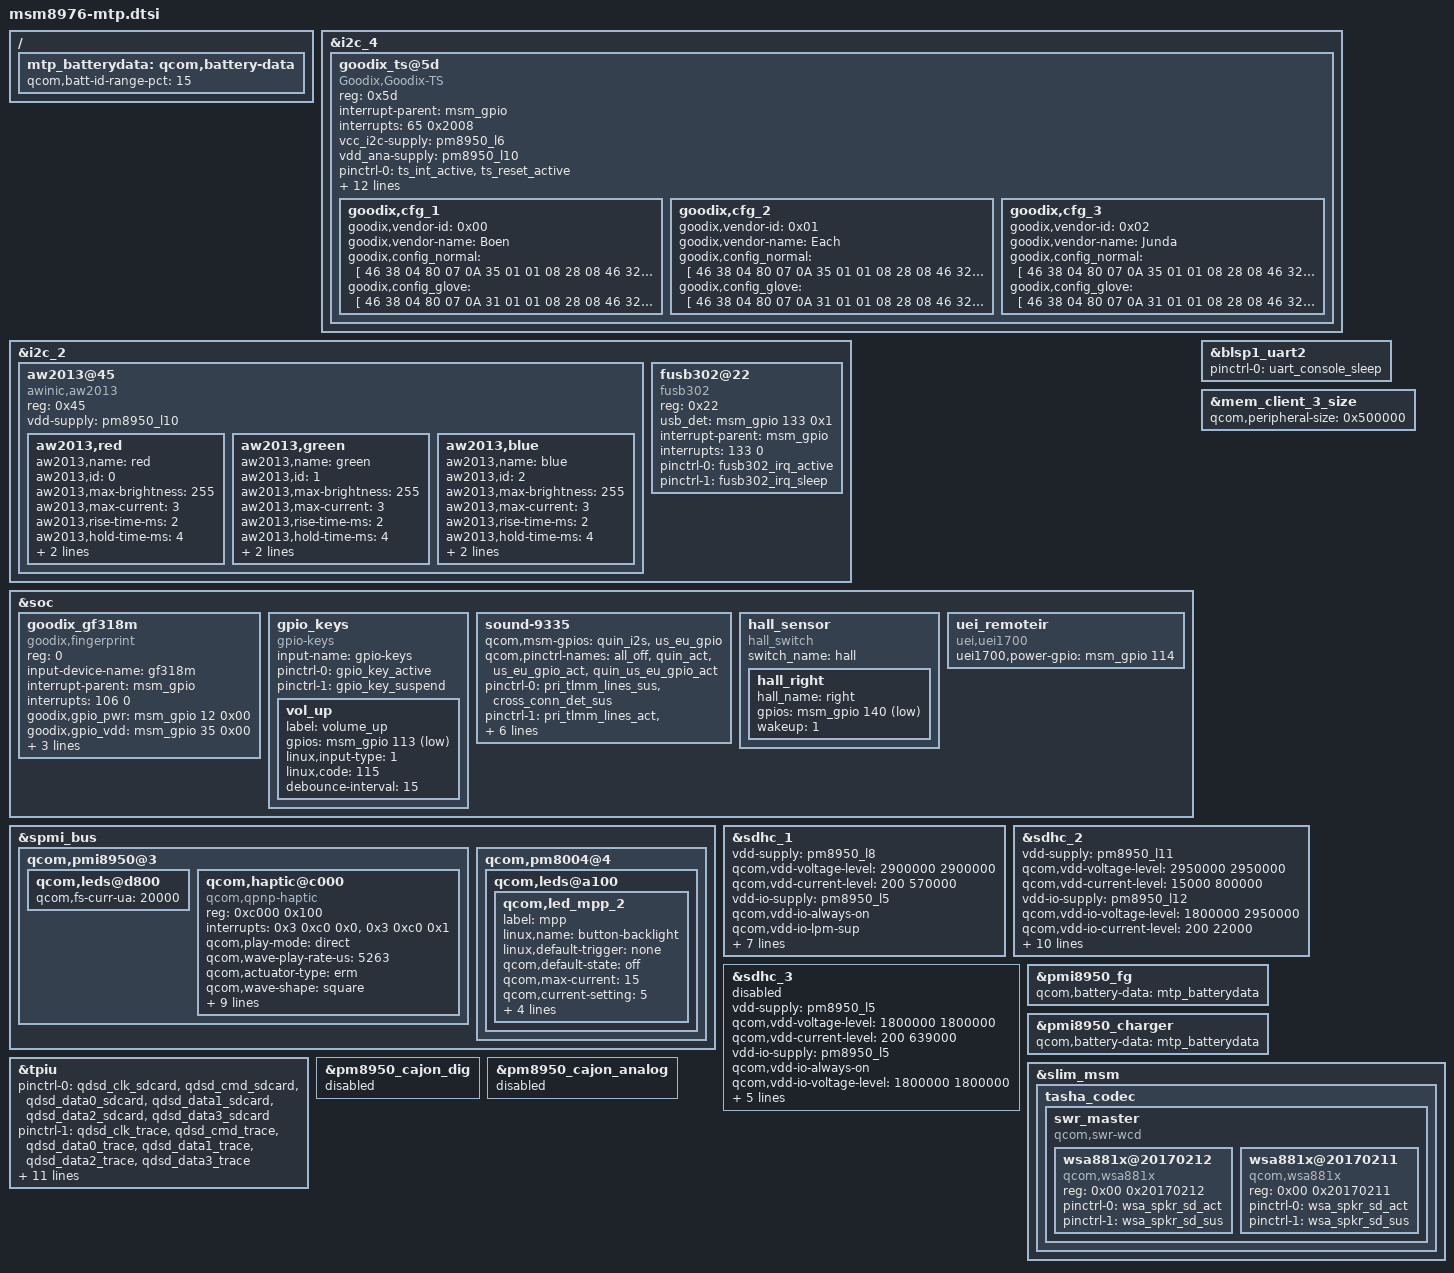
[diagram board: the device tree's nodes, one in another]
/*
 * Copyright (c) 2015, The Linux Foundation. All rights reserved.
 *
 * This program is free software; you can redistribute it and/or modify
 * it under the terms of the GNU General Public License version 2 and
 * only version 2 as published by the Free Software Foundation.
 *
 * This program is distributed in the hope that it will be useful,
 * but WITHOUT ANY WARRANTY; without even the implied warranty of
 * MERCHANTABILITY or FITNESS FOR A PARTICULAR PURPOSE.  See the
 * GNU General Public License for more details.
 */

#include "msm8976-pinctrl.dtsi"
#include "msm8976-camera-sensor-mtp.dtsi"
#include "msm8976-mdss-mtp.dtsi"
#include "msm8976-wsa881x.dtsi"

&i2c_4 { /* BLSP1 QUP4 */
	goodix_ts@5d {
		compatible = "Goodix,Goodix-TS";
		reg = <0x5d>;
		interrupt-parent = <&msm_gpio>;
		interrupts = <65 0x2008>;
		vcc_i2c-supply = <&pm8950_l6>;
		vdd_ana-supply = <&pm8950_l10>;
		/* pins used by touchscreen */
		pinctrl-names = "pmx_ts_active","pmx_ts_suspend";
		pinctrl-0 = <&ts_int_active &ts_reset_active>;
		pinctrl-1 = <&ts_int_suspend &ts_reset_suspend>;
		goodix,irq-gpio = <&msm_gpio 65 0x2008>;
		goodix,reset-gpio = <&msm_gpio 64 0x0>;
		goodix,irq_flags = <0x2>;
		goodix,pixel = <1080 1920>;
		goodix,pwr_ctrl = <1>;
		goodix,vddio = "vcc_i2c";
		goodix,vdd = "vdd_ana";
		goodix,ic_type = "GT915L";
		goodix,charger_status_force_check = <0>;
		goodix,cover = <0 0 540 300>; //x_min, y_min, x_max, y_max
		goodix,resume-in-workqueue;
		/*touch config file*/
		goodix,cfg_1 {
			goodix,vendor-id = <0x00>;
			goodix,vendor-name = "Boen";
			goodix,config_normal = [
				46 38 04 80 07 0A 35 01 01 08 28 08 46 32 03 07
				00 01 00 00 00 00 00 14 14 24 14 8C 2E 0E 34 36
				D6 09 D6 09 00 A1 33 11 00 00 00 00 00 00 00 00
				00 00 11 23 58 94 D0 02 00 00 00 04 B1 26 00 9A
				2E 1E 89 37 00 7A 43 00 70 50 00 70 18 40 60 00
				F0 4A 3A EE E0 27 00 00 00 00 00 00 00 00 EF 01
				00 00 00 00 10 01 32 00 00 19 00 00 00 00 00 28
				10 12 14 16 18 1A 1C 0E 0C 0A 08 06 04 02 00 00
				00 00 00 00 00 00 00 00 00 00 00 00 00 00 0A 08
				06 04 02 00 0C 0F 10 12 13 14 16 2A 29 28 26 24
				22 21 20 1F 1E 1D 1C 18 00 00 00 00 00 00 00 00
				00 00 00 00 00 00 00 00 B1 01
				];
			goodix,config_glove = [
				46 38 04 80 07 0A 31 01 01 08 28 08 46 32 03 07
				00 01 00 00 00 00 00 18 1A 1E 14 8C 2E 0E 57 59
				EE 06 D6 09 00 A2 34 11 0A 14 14 03 1E 00 00 00
				00 00 11 32 7D 94 D0 02 00 00 00 04 B1 37 00 9B
				42 14 89 4F 00 7B 5F 00 70 72 00 70 18 40 60 00
				F0 4A 3A FF F0 27 00 00 00 03 1E 28 00 28 FF 03
				00 00 00 00 10 01 32 00 00 19 46 1E 28 00 28 28
				10 12 14 16 18 1A 1C 0E 0C 0A 08 06 04 02 00 00
				00 00 00 00 00 00 00 00 00 00 00 00 00 00 0A 08
				06 04 02 00 0C 0F 10 12 13 14 16 2A 29 28 26 24
				22 21 20 1F 1E 1D 1C 18 00 00 00 00 00 00 00 00
				00 00 00 00 00 00 00 00 02 01
				];
		};
		goodix,cfg_2 {
			goodix,vendor-id = <0x01>;
			goodix,vendor-name = "Each";
			goodix,config_normal = [
				46 38 04 80 07 0A 35 01 01 08 28 08 46 32 03 07
				00 01 00 00 00 00 00 14 14 24 14 8C 2E 0E 34 36
				D6 09 D6 09 00 A1 33 11 00 00 00 00 00 00 00 00
				00 00 11 23 58 94 D0 02 00 00 00 04 B1 26 00 9A
				2E 1E 89 37 00 79 43 00 6F 50 00 6F 18 40 60 00
				F0 4A 3A EE E0 27 00 00 00 00 00 00 00 00 EF 01
				00 00 00 00 10 01 32 00 00 19 00 00 00 00 00 28
				1C 1A 18 16 14 12 10 0E 0C 0A 08 06 04 02 00 00
				00 00 00 00 00 00 00 00 00 00 00 00 00 00 14 13
				12 10 0F 0C 0A 08 06 04 02 00 18 16 1C 1D 1E 1F
				20 22 24 26 21 28 29 2A 00 00 00 00 00 00 00 00
				00 00 00 00 00 00 00 00 B4 01
				];
			goodix,config_glove = [
				46 38 04 80 07 0A 31 01 01 08 28 08 46 32 03 07
				00 01 00 00 00 00 00 18 1A 1E 14 8C 2E 0E 57 59
				EE 06 D6 09 00 A2 34 11 0A 14 14 03 1E 00 00 00
				00 00 11 32 7D 94 D0 02 00 00 00 04 B2 37 00 9B
				42 14 89 4F 00 7A 5F 00 6F 72 00 6F 18 40 60 00
				F0 4A 3A FF F0 27 00 00 00 03 1E 28 00 28 FF 03
				00 00 00 00 10 01 32 00 00 19 46 1E 28 00 28 28
				1C 1A 18 16 14 12 10 0E 0C 0A 08 06 04 02 00 00
				00 00 00 00 00 00 00 00 00 00 00 00 00 00 14 13
				12 10 0F 0C 0A 08 06 04 02 00 18 16 1C 1D 1E 1F
				20 22 24 26 21 28 29 2A 00 00 00 00 00 00 00 00
				00 00 00 00 00 00 00 00 04 01
				];
		};
		goodix,cfg_3 {
			goodix,vendor-id = <0x02>;
			goodix,vendor-name = "Junda";
			goodix,config_normal = [
				46 38 04 80 07 0A 35 01 01 08 28 08 46 32 03 07 
				00 01 00 00 10 10 00 14 14 24 14 8C 2E 0E 34 36 
				D6 09 D6 09 00 A1 33 11 00 00 00 00 00 00 00 00 
				00 00 11 23 58 94 D0 02 00 00 00 04 B1 26 00 9A 
				2E 1E 89 37 00 79 43 00 6F 50 00 6F 18 40 60 00 
				F0 4A 3A EE E0 27 00 00 00 00 00 00 00 00 EF 01 
				00 00 00 00 10 01 32 00 00 19 00 00 00 00 00 28 
				02 04 06 1C 1A 18 16 14 12 10 0E 0C 0A 08 00 00 
				00 00 00 00 00 00 00 00 00 00 00 00 00 00 18 1C 
				1D 1E 1F 20 2A 22 24 26 21 28 29 16 12 10 0F 0C 
				0A 08 06 04 02 00 14 13 00 00 00 00 00 00 00 00 
				00 00 00 00 00 00 00 00 94 01
				];
			goodix,config_glove = [
				46 38 04 80 07 0A 31 01 01 08 28 08 46 32 03 07 
				00 01 00 00 10 10 00 18 1A 1E 14 8C 2E 0E 57 59 
				EE 06 D6 09 00 A2 34 11 0A 14 14 03 1E 00 00 00 
				00 00 11 32 7D 94 D0 02 00 00 00 04 B1 37 00 9B 
				42 14 89 4F 00 7B 5F 00 70 72 00 70 18 40 60 00 
				F0 4A 3A FF F0 27 00 00 00 03 1E 28 00 28 EF 03 
				00 00 00 00 10 01 32 00 00 19 00 1E 28 00 28 28 
				02 04 06 1C 1A 18 16 14 12 10 0E 0C 0A 08 00 00 
				00 00 00 00 00 00 00 00 00 00 00 00 00 00 18 1C 
				1D 1E 1F 20 2A 22 24 26 21 28 29 16 12 10 0F 0C 
				0A 08 06 04 02 00 14 13 00 00 00 00 00 00 00 00 
				00 00 00 00 00 00 00 00 38 01
				];
		};
	};
};

&i2c_2 {

	aw2013@45 {
		compatible = "awinic,aw2013";
		reg = <0x45>;
		vdd-supply = <&pm8950_l10>;
		/*
		    pinctrl-names = "default","sleep";
		    pinctrl-0 = <&led_default>;
		    pinctrl-1 = <&led_sleep>;*/
		aw2013,red {
			aw2013,name = "red";
			aw2013,id = <0>;
			aw2013,max-brightness = <255>;
			aw2013,max-current = <3>;
			/*LAFITE-161 yanzhiyao 20160108 begin*/
			aw2013,rise-time-ms = <2>;
			aw2013,hold-time-ms = <4>;
			aw2013,fall-time-ms = <2>;
			aw2013,off-time-ms = <3>;
			/*LAFITE-161 yanzhiyao 20160108 end*/
		};
		aw2013,green {
			aw2013,name = "green";
			aw2013,id = <1>;
			aw2013,max-brightness = <255>;
			aw2013,max-current = <3>;
			/*LAFITE-161 yanzhiyao 20160108 begin*/
			aw2013,rise-time-ms = <2>;
			aw2013,hold-time-ms = <4>;
			aw2013,fall-time-ms = <2>;
			aw2013,off-time-ms = <3>;
			/*LAFITE-161 yanzhiyao 20160108 end*/
		};
		aw2013,blue {
			aw2013,name = "blue";
			aw2013,id = <2>;
			aw2013,max-brightness = <255>;
			aw2013,max-current = <3>;
			/*LAFITE-161 yanzhiyao 20160108 begin*/
			aw2013,rise-time-ms = <2>;
			aw2013,hold-time-ms = <4>;
			aw2013,fall-time-ms = <2>;
			aw2013,off-time-ms = <3>;
			/*LAFITE-161 yanzhiyao 20160108 end*/
		};
	};

	/* add usb type c for fusb302 */
	fusb302@22 {
		compatible = "fusb302";
		reg = <0x22>;
		usb_det = <&msm_gpio 133 0x1>;
		interrupt-parent = <&msm_gpio>;
		interrupts = <133 0>;
		interrupt-names = "usb_det_int";
		pinctrl-names = "default", "sleep";
		pinctrl-0 = <&fusb302_irq_active>;
		pinctrl-1 = <&fusb302_irq_sleep>;
	};
};

&soc {
	goodix_gf318m {
		compatible = "goodix,fingerprint";
		reg = <0>;

		input-device-name = "gf318m";
		interrupt-parent = <&msm_gpio>;
		interrupts = <106 0>;

		/*vcc_spi-supply  = <&pm8950_l10>;*/
		/*vdd_ana-supply  = <&pm8950_l10>;*/
		/*vdd_io-supply   = <&pm8950_l6>;*/
		/*qcom,vdd_ana-always-on; */

		goodix,gpio_pwr= <&msm_gpio 12 0x00>;
		goodix,gpio_vdd= <&msm_gpio 35 0x00>;

		goodix,gpio_reset = <&msm_gpio 13 0x00>;
		goodix,gpio_irq = <&msm_gpio 106 0x00>;

		pinctrl-names = "goodix_irq_active";
		pinctrl-0 = <&goodix_irq_active>;

                /*pinctrl-names = "default";*/
        };



	gpio_keys {
		compatible = "gpio-keys";
		input-name = "gpio-keys";
		pinctrl-names = "tlmm_gpio_key_active","tlmm_gpio_key_suspend";
		pinctrl-0 = <&gpio_key_active>;
		pinctrl-1 = <&gpio_key_suspend>;

		vol_up {
			label = "volume_up";
			gpios = <&msm_gpio 113 0x1>;
			linux,input-type = <1>;
			linux,code = <115>;
			debounce-interval = <15>;
		};
	};

	sound-9335 {
		qcom,msm-gpios =
			"quin_i2s",
			"us_eu_gpio";
		qcom,pinctrl-names =
			"all_off",
			"quin_act",
			"us_eu_gpio_act",
			"quin_us_eu_gpio_act";
		pinctrl-names =
			"all_off",
			"quin_act",
			"us_eu_gpio_act",
			"quin_us_eu_gpio_act";
		pinctrl-0 = <&pri_tlmm_lines_sus &cross_conn_det_sus>;
		pinctrl-1 = <&pri_tlmm_lines_act &cross_conn_det_sus>;
		pinctrl-2 = <&pri_tlmm_lines_sus &cross_conn_det_act>;
		pinctrl-3 = <&pri_tlmm_lines_act &cross_conn_det_act>;
		qcom,cdc-us-euro-gpios = <&msm_gpio 144 0>;
	};

	/*yulong add for HALL sensor*/
	hall_sensor {
		compatible = "hall_switch";
		switch_name = "hall";
		hall_right {
			hall_name = "right";
			gpios = <&msm_gpio 140 0x1>;
			wakeup = <1>;
		};
	};

	uei_remoteir {
		compatible = "uei,uei1700";
		uei1700,power-gpio = <&msm_gpio 114 0>;
	};
};

&blsp1_uart2 {
	status = "ok";
	pinctrl-names = "default";
	pinctrl-0 = <&uart_console_sleep>;
};

&mem_client_3_size {
	qcom,peripheral-size = <0x500000>;
};

&spmi_bus {
	qcom,pmi8950@3 {
		qcom,leds@d800 {
			qcom,fs-curr-ua = <20000>;
		};

		qcom,haptic@c000 {
			compatible = "qcom,qpnp-haptic";
			reg = <0xc000 0x100>;
			interrupts = <0x3 0xc0 0x0>,
				<0x3 0xc0 0x1>;
			interrupt-names = "sc-irq", "play-irq";
			qcom,play-mode = "direct";
			qcom,wave-play-rate-us = <5263>;
			qcom,actuator-type = "erm";
			qcom,wave-shape = "square";
			qcom,vmax-mv = <3300>;
			qcom,ilim-ma = <100>;
			qcom,sc-deb-cycles = <8>;
			qcom,int-pwm-freq-khz = <505>;
			/*qcom,en-brake;
			qcom,brake-pattern = [03 03 00 00];*/
			qcom,use-play-irq;
			qcom,use-sc-irq;
			qcom,wave-samples = [3e 3e 3e 3e 3e 3e 3e 3e];
			qcom,wave-rep-cnt = <1>;
			qcom,wave-samp-rep-cnt = <1>;
			/*qcom,lra-auto-res-mode="qwd";
			qcom,lra-high-z="opt1";
			qcom,lra-res-cal-period = <0>;
			qcom,correct-lra-drive-freq;
			qcom,misc-trim-error-rc19p2-clk-reg-present;*/
		};
	};

	qcom,pm8004@4 {
		qcom,leds@a100 {
			status = "okay";
			qcom,led_mpp_2 {
				label = "mpp";
				linux,name = "button-backlight";
				linux,default-trigger = "none";
				qcom,default-state = "off";
				qcom,max-current = <15>;
				qcom,current-setting = <5>;
				qcom,id = <6>;
				qcom,mode = "manual";
				qcom,source-sel = <1>;
				qcom,mode-ctrl = <0x60>;
			};
		};
	};
};

&sdhc_1 {
	vdd-supply = <&pm8950_l8>;
	qcom,vdd-voltage-level = <2900000 2900000>;
	qcom,vdd-current-level = <200 570000>;

	vdd-io-supply = <&pm8950_l5>;
	qcom,vdd-io-always-on;
	qcom,vdd-io-lpm-sup;
	qcom,vdd-io-voltage-level = <1800000 1800000>;
	qcom,vdd-io-current-level = <200 325000>;

	pinctrl-names = "active", "sleep";
	pinctrl-0 = <&sdc1_clk_on &sdc1_cmd_on &sdc1_data_on &sdc1_rclk_on>;
	pinctrl-1 = <&sdc1_clk_off &sdc1_cmd_off &sdc1_data_off &sdc1_rclk_off>;

	qcom,nonremovable;

	status = "ok";
};

&sdhc_2 {
	vdd-supply = <&pm8950_l11>;
	qcom,vdd-voltage-level = <2950000 2950000>;
	qcom,vdd-current-level = <15000 800000>;

	vdd-io-supply = <&pm8950_l12>;
	qcom,vdd-io-voltage-level = <1800000 2950000>;
	qcom,vdd-io-current-level = <200 22000>;

	pinctrl-names = "active", "sleep";
	pinctrl-0 = <&sdc2_clk_on &sdc2_cmd_on &sdc2_data_on &sdc2_cd_on>;
	pinctrl-1 = <&sdc2_clk_off &sdc2_cmd_off &sdc2_data_off &sdc2_cd_off>;

	#address-cells = <0>;
	interrupt-parent = <&sdhc_2>;
	interrupts = <0 1 2>;
	#interrupt-cells = <1>;
	interrupt-map-mask = <0xffffffff>;
	interrupt-map = <0 &intc 0 125 0
			1 &intc 0 221 0
			2 &msm_gpio 100 0>;
	interrupt-names = "hc_irq", "pwr_irq", "status_irq";
	cd-gpios = <&msm_gpio 100 0x1>;

	status = "ok";
};

&sdhc_3 {
	vdd-supply = <&pm8950_l5>;
	qcom,vdd-voltage-level = <1800000 1800000>;
	qcom,vdd-current-level = <200 639000>;

	vdd-io-supply = <&pm8950_l5>;
	qcom,vdd-io-always-on;
	qcom,vdd-io-voltage-level = <1800000 1800000>;
	qcom,vdd-io-current-level = <200 639000>;

	pinctrl-names = "active", "sleep";
	pinctrl-0 = <&sdc3_clk_on &sdc3_cmd_on &sdc3_dat_on
					&sdc3_wlan_gpio_active>;
	pinctrl-1 = <&sdc3_clk_off &sdc3_cmd_off &sdc3_dat_off
					&sdc3_wlan_gpio_sleep>;

	status = "disabled";
};

/{
	mtp_batterydata: qcom,battery-data {
		qcom,batt-id-range-pct = <15>;
		#include "Batterydata_CPLD403_Lishen_4000mAh_4400mv.dtsi"
		#include "Batterydata_CPLD403_Coslight_4000mAh_4400mv.dtsi"
	};
};

&pmi8950_fg {
	qcom,battery-data = <&mtp_batterydata>;
};

&pmi8950_charger {
	qcom,battery-data = <&mtp_batterydata>;
	/*qcom,chg-led-support;*/
	/*qcom,chg-led-sw-controls;*/
};

/* CoreSight */
&tpiu {
	pinctrl-names = "sdcard", "trace", "swduart",
			"swdtrc", "jtag", "spmi";
	/* NIDnT */
	pinctrl-0 = <&qdsd_clk_sdcard &qdsd_cmd_sdcard
		     &qdsd_data0_sdcard &qdsd_data1_sdcard
		     &qdsd_data2_sdcard &qdsd_data3_sdcard>;
	pinctrl-1 = <&qdsd_clk_trace &qdsd_cmd_trace
		     &qdsd_data0_trace &qdsd_data1_trace
		     &qdsd_data2_trace &qdsd_data3_trace>;
	pinctrl-2 = <&qdsd_cmd_swduart &qdsd_data0_swduart
		     &qdsd_data1_swduart &qdsd_data2_swduart
		     &qdsd_data3_swduart>;
	pinctrl-3 = <&qdsd_clk_swdtrc &qdsd_cmd_swdtrc
		     &qdsd_data0_swdtrc &qdsd_data1_swdtrc
		     &qdsd_data2_swdtrc &qdsd_data3_swdtrc>;
	pinctrl-4 = <&qdsd_cmd_jtag &qdsd_data0_jtag
		     &qdsd_data1_jtag &qdsd_data2_jtag
		     &qdsd_data3_jtag>;
	pinctrl-5 = <&qdsd_clk_spmi &qdsd_cmd_spmi
		     &qdsd_data0_spmi &qdsd_data3_spmi>;
};

&slim_msm {
	tasha_codec {
		swr_master {
			compatible = "qcom,swr-wcd";
			#address-cells = <2>;
			#size-cells = <0>;
			wsa881x@20170212 {
				compatible = "qcom,wsa881x";
				reg = <0x00 0x20170212>;
				pinctrl-names = "wsa_spkr_sd_act",
						"wsa_spkr_sd_sus";
				pinctrl-0 = <&wsa_spkr_sd_act>;
				pinctrl-1 = <&wsa_spkr_sd_sus>;
			};

			wsa881x@20170211 {
				compatible = "qcom,wsa881x";
				reg = <0x00 0x20170211>;
				pinctrl-names = "wsa_spkr_sd_act",
						"wsa_spkr_sd_sus";
				pinctrl-0 = <&wsa_spkr_sd_act>;
				pinctrl-1 = <&wsa_spkr_sd_sus>;
			};
		};
	};
};

&pm8950_cajon_dig {
	status = "disabled";
};

&pm8950_cajon_analog {
	status = "disabled";
};
